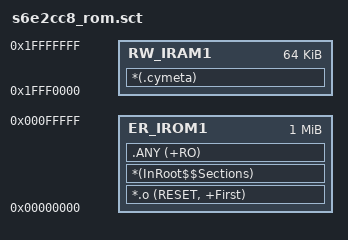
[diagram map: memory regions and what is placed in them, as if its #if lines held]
#! armcc -E
/*******************************************************************************
* \file     s6e2cc8_rom.sct
* 
* \version  1.0
*
* \brief    Linker file for the Keil ARM C/C++ Compiler
*
********************************************************************************
* Copyright 2016, Cypress Semiconductor Corporation. All rights reserved.
* You may use this file only in accordance with the license, terms, conditions,
* disclaimers, and limitations in the end user license agreement accompanying
* the software package with which this file was provided.
* CYPRESS PROVIDES THIS SOFTWARE "AS IS" AND MAKES NO WARRANTY
* OF ANY KIND, EXPRESS OR IMPLIED, WITH REGARD TO THIS SOFTWARE,
* INCLUDING, BUT NOT LIMITED TO, THE IMPLIED WARRANTIES OF
* MERCHANTABILITY, NON-INFRINGEMENT AND FITNESS FOR A PARTICULAR
* PURPOSE.
*******************************************************************************/

#define IRAM1_START 0x1FFF0000
#define IRAM1_SIZE  0x00010000
#define IRAM2_START 0x20038000
#define IRAM2_SIZE  0x00010000
#define IROM1_START 0x00000000
#define IROM1_SIZE  0x00100000
#define IROM2_START 0x00406000
#define IROM2_SIZE  0x0000A000

LR_IROM1 IROM1_START IROM1_SIZE  {    ; load region size_region
  ER_IROM1 IROM1_START IROM1_SIZE  {  ; load address = execution address
   *.o (RESET, +First)
   *(InRoot$$Sections)
   .ANY (+RO)
  }
  RW_IRAM1 IRAM1_START IRAM1_SIZE  {  ; RW data
   .ANY (+RW +ZI)
  }
}
#ifdef INCLUDE_CYMETADATA
CYMETA 0x90500000 {
    .cymeta + 0 { *(.cymeta) }
}
#endif
